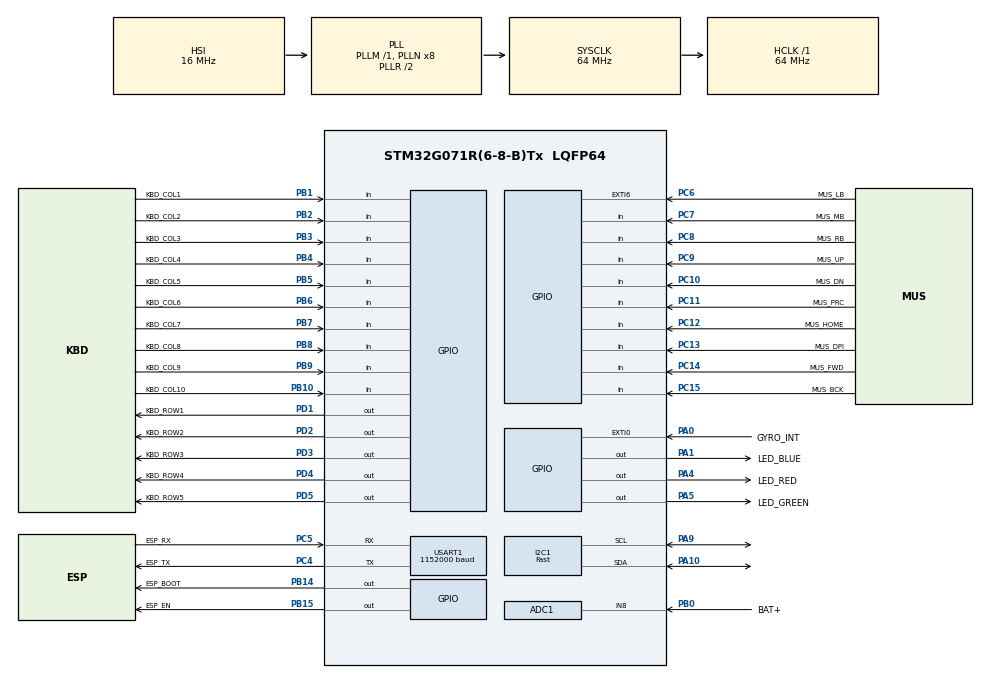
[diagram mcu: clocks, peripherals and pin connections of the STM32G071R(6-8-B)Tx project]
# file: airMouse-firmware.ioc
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ADC1.Channel-4\#ChannelRegularConversion=ADC_CHANNEL_8
ADC1.NbrOfConversionFlag=1
ADC1.Rank-4\#ChannelRegularConversion=1
ADC1.SamplingTime-4\#ChannelRegularConversion=ADC_SAMPLINGTIME_COMMON_1
ADC1.SelectedChannel=ADC_CHANNEL_8
ADC1.master=1
I2C1.CustomTiming=Disabled
I2C1.I2C_Speed_Mode=I2C_Fast
I2C1.Timing=0x00300617
Mcu.Family=STM32G0
Mcu.Name=STM32G071R(6-8-B)Tx
Mcu.Package=LQFP64
NVIC.EXTI0_1_IRQn=true\:0\:0\:false\:false\:true\:true\:true\:true
NVIC.EXTI4_15_IRQn=true\:0\:0\:false\:false\:true\:true\:true\:true
PA0.GPIO_Label=GYRO_INT
PA0.GPIO_PuPd=GPIO_NOPULL
PA0.Signal=GPXTI0
PA1.GPIO_Label=LED_BLUE
PA1.Signal=GPIO_Output
PA10.GPIO_Pu=GPIO_NOPULL
PA10.Mode=I2C
PA10.Signal=I2C1_SDA
PA4.GPIO_Label=LED_RED
PA4.Signal=GPIO_Output
PA5.GPIO_Label=LED_GREEN
PA5.Signal=GPIO_Output
PA9.GPIO_Pu=GPIO_NOPULL
PA9.Mode=I2C
PA9.Signal=I2C1_SCL
PB0.GPIO_Label=BAT+
PB0.Mode=IN8
PB0.Signal=ADC1_IN8
PB1.GPIO_Label=KBD_COL1
PB1.GPIO_PuPd=GPIO_PULLUP
PB1.Signal=GPIO_Input
PB10.GPIO_Label=KBD_COL10
PB10.GPIO_PuPd=GPIO_PULLUP
PB10.Signal=GPIO_Input
PB14.GPIO_Label=ESP_BOOT
PB14.GPIO_ModeDefaultOutputPP=GPIO_MODE_OUTPUT_OD
PB14.GPIO_PuPd=GPIO_NOPULL
PB14.PinState=GPIO_PIN_SET
PB14.Signal=GPIO_Output
PB15.GPIO_Label=ESP_EN
PB15.GPIO_ModeDefaultOutputPP=GPIO_MODE_OUTPUT_PP
PB15.GPIO_PuPd=GPIO_NOPULL
PB15.PinState=GPIO_PIN_RESET
PB15.Signal=GPIO_Output
PB2.GPIO_Label=KBD_COL2
PB2.GPIO_PuPd=GPIO_PULLUP
PB2.Signal=GPIO_Input
PB3.GPIO_Label=KBD_COL3
PB3.GPIO_PuPd=GPIO_PULLUP
PB3.Signal=GPIO_Input
PB4.GPIO_Label=KBD_COL4
PB4.GPIO_PuPd=GPIO_PULLUP
PB4.Signal=GPIO_Input
PB5.GPIO_Label=KBD_COL5
PB5.GPIO_PuPd=GPIO_PULLUP
PB5.Signal=GPIO_Input
PB6.GPIO_Label=KBD_COL6
PB6.GPIO_PuPd=GPIO_PULLUP
PB6.Signal=GPIO_Input
PB7.GPIO_Label=KBD_COL7
PB7.GPIO_PuPd=GPIO_PULLUP
PB7.Signal=GPIO_Input
PB8.GPIO_Label=KBD_COL8
PB8.GPIO_PuPd=GPIO_PULLUP
PB8.Signal=GPIO_Input
PB9.GPIO_Label=KBD_COL9
PB9.GPIO_PuPd=GPIO_PULLUP
PB9.Signal=GPIO_Input
PC10.GPIO_Label=MUS_DN
PC10.GPIO_PuPd=GPIO_PULLUP
PC10.Signal=GPIO_Input
PC11.GPIO_Label=MUS_PRC
PC11.GPIO_PuPd=GPIO_PULLUP
PC11.Signal=GPIO_Input
PC12.GPIO_Label=MUS_HOME
PC12.GPIO_PuPd=GPIO_PULLUP
PC12.Signal=GPIO_Input
PC13.GPIO_Label=MUS_DPI
PC13.GPIO_PuPd=GPIO_PULLUP
PC13.Signal=GPIO_Input
PC14-OSC32_IN\ (PC14).GPIO_Label=MUS_FWD
PC14-OSC32_IN\ (PC14).GPIO_PuPd=GPIO_PULLUP
PC14-OSC32_IN\ (PC14).Signal=GPIO_Input
PC15-OSC32_OUT\ (PC15).GPIO_Label=MUS_BCK
PC15-OSC32_OUT\ (PC15).GPIO_PuPd=GPIO_PULLUP
PC15-OSC32_OUT\ (PC15).Signal=GPIO_Input
PC4.GPIO_Label=ESP_TX
PC4.Mode=Asynchronous
PC4.Signal=USART1_TX
PC5.GPIO_Label=ESP_RX
PC5.GPIO_ModeDefaultPP=GPIO_MODE_AF_OD
PC5.GPIO_PuPd=GPIO_NOPULL
PC5.Mode=Asynchronous
PC5.Signal=USART1_RX
PC6.GPIO_Label=MUS_LB
PC6.GPIO_ModeDefaultEXTI=GPIO_MODE_IT_FALLING
PC6.GPIO_PuPd=GPIO_PULLUP
PC6.Signal=GPXTI6
PC7.GPIO_Label=MUS_MB
PC7.GPIO_PuPd=GPIO_PULLUP
PC7.Signal=GPIO_Input
PC8.GPIO_Label=MUS_RB
PC8.GPIO_PuPd=GPIO_PULLUP
PC8.Signal=GPIO_Input
PC9.GPIO_Label=MUS_UP
PC9.GPIO_PuPd=GPIO_PULLUP
PC9.Signal=GPIO_Input
PD1.GPIO_Label=KBD_ROW1
PD1.Signal=GPIO_Output
PD2.GPIO_Label=KBD_ROW2
PD2.Signal=GPIO_Output
PD3.GPIO_Label=KBD_ROW3
PD3.Signal=GPIO_Output
PD4.GPIO_Label=KBD_ROW4
PD4.Signal=GPIO_Output
PD5.GPIO_Label=KBD_ROW5
PD5.Signal=GPIO_Output
ProjectManager.HeapSize=0x200
ProjectManager.StackSize=0x400
ProjectManager.TargetToolchain=STM32CubeIDE
RCC.ADCFreq_Value=64000000
RCC.AHBFreq_Value=64000000
RCC.CortexFreq_Value=64000000
RCC.EXTERNAL_CLOCK_VALUE=48000
RCC.HCLKFreq_Value=64000000
RCC.HSE_VALUE=8000000
RCC.HSI_VALUE=16000000
RCC.I2C1CLockSelection=RCC_I2C1CLKSOURCE_HSI
RCC.LSE_VALUE=32768
RCC.SYSCLKFreq_VALUE=64000000
RCC.SYSCLKSource=RCC_SYSCLKSOURCE_PLLCLK
RCC.VCOOutputFreq_Value=128000000
USART1.BaudRate=1152000
USART1.FIFOMode=FIFOMODE_ENABLE
USART1.OneBitSampling=UART_ONE_BIT_SAMPLE_DISABLE
USART1.OverrunDisableParam=ADVFEATURE_OVERRUN_DISABLE
USART1.VirtualMode-Asynchronous=VM_ASYNC
board=custom

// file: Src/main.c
/* USER CODE BEGIN Header */
/**
 ******************************************************************************
 * @file           : main.c
 * @brief          : Main program body
 ******************************************************************************
 * @attention
 *
 * Copyright (c) 2025 STMicroelectronics.
 * All rights reserved.
 *
 * This software is licensed under terms that can be found in the LICENSE file
 * in the root directory of this software component.
 * If no LICENSE file comes with this software, it is provided AS-IS.
 *
 ******************************************************************************
 */
/* USER CODE END Header */
#include "main.h"
#include "adc.h"
#include "i2c.h"
#include "usart.h"
#include "gpio.h"

/* USER CODE BEGIN Includes */
#include "airmouse.h"
/* USER CODE END Includes */

void SystemClock_Config(void);

int main(void)
{

  /* MCU Configuration--------------------------------------------------------*/

  /* Reset of all peripherals, Initializes the Flash interface and the Systick. */
  HAL_Init();

  /* Configure the system clock */
  SystemClock_Config();

  /* Initialize all configured peripherals */
  MX_GPIO_Init();
  MX_USART1_UART_Init();
  MX_I2C1_Init();
  MX_ADC1_Init();
  /* USER CODE BEGIN 2 */

	airMouseSetup();

  /* USER CODE END 2 */

  /* Infinite loop */
  /* USER CODE BEGIN WHILE */
	while (1) {
		airMouseProcess();
    /* USER CODE END WHILE */

	}
}

void SystemClock_Config(void)
{
  RCC_OscInitTypeDef RCC_OscInitStruct = {0};
  RCC_ClkInitTypeDef RCC_ClkInitStruct = {0};

  /** Configure the main internal regulator output voltage
  */
  HAL_PWREx_ControlVoltageScaling(PWR_REGULATOR_VOLTAGE_SCALE1);

  /** Initializes the RCC Oscillators according to the specified parameters
  * in the RCC_OscInitTypeDef structure.
  */
  RCC_OscInitStruct.OscillatorType = RCC_OSCILLATORTYPE_HSI;
  RCC_OscInitStruct.HSIState = RCC_HSI_ON;
  RCC_OscInitStruct.HSIDiv = RCC_HSI_DIV1;
  RCC_OscInitStruct.HSICalibrationValue = RCC_HSICALIBRATION_DEFAULT;
  RCC_OscInitStruct.PLL.PLLState = RCC_PLL_ON;
  RCC_OscInitStruct.PLL.PLLSource = RCC_PLLSOURCE_HSI;
  RCC_OscInitStruct.PLL.PLLM = RCC_PLLM_DIV1;
  RCC_OscInitStruct.PLL.PLLN = 8;
  RCC_OscInitStruct.PLL.PLLP = RCC_PLLP_DIV2;
  RCC_OscInitStruct.PLL.PLLQ = RCC_PLLQ_DIV2;
  RCC_OscInitStruct.PLL.PLLR = RCC_PLLR_DIV2;
  if (HAL_RCC_OscConfig(&RCC_OscInitStruct) != HAL_OK)
  {
    Error_Handler();
  }

  /** Initializes the CPU, AHB and APB buses clocks
  */
  RCC_ClkInitStruct.ClockType = RCC_CLOCKTYPE_HCLK|RCC_CLOCKTYPE_SYSCLK
                              |RCC_CLOCKTYPE_PCLK1;
  RCC_ClkInitStruct.SYSCLKSource = RCC_SYSCLKSOURCE_PLLCLK;
  RCC_ClkInitStruct.AHBCLKDivider = RCC_SYSCLK_DIV1;
  RCC_ClkInitStruct.APB1CLKDivider = RCC_HCLK_DIV1;

  if (HAL_RCC_ClockConfig(&RCC_ClkInitStruct, FLASH_LATENCY_2) != HAL_OK)
  {
    Error_Handler();
  }
}

void Error_Handler(void)
{
	__disable_irq();
	while (1) {
	}
}
